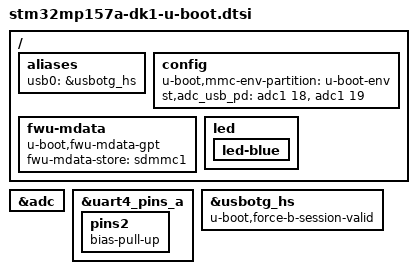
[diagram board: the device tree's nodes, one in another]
// SPDX-License-Identifier: GPL-2.0-or-later OR BSD-3-Clause
/*
 * Copyright : STMicroelectronics 2022
 */

#include <dt-bindings/input/linux-event-codes.h>
#include "stm32mp15-scmi-u-boot.dtsi"

/ {
	aliases {
		usb0 = &usbotg_hs;
	};

	config {
		u-boot,mmc-env-partition = "u-boot-env";
		st,adc_usb_pd = <&adc1 18>, <&adc1 19>;
	};

	fwu-mdata {
		compatible = "u-boot,fwu-mdata-gpt";
		fwu-mdata-store = <&sdmmc1>;
	};

	led {
		led-blue {
			/delete-property/label;
		};
	};
};

&adc {
	status = "okay";
};

&uart4_pins_a {
	pins2 {
		/* pull-up on rx to avoid floating level */
		bias-pull-up;
	};
};

&usbotg_hs {
	u-boot,force-b-session-valid;
};
